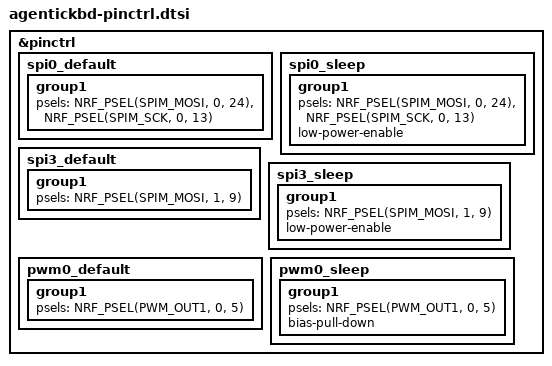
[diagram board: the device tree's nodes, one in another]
// This file was generated from a template. Edit it to match your keyboard.
// See https://docs.zephyrproject.org/4.1.0/hardware/porting/board_porting.html
// and https://docs.zephyrproject.org/4.1.0/hardware/pinctrl/index.html for
// more instructions.

#include <dt-bindings/pinctrl/nrf-pinctrl.h>

&pinctrl {
    // uart0_default: uart0_default {
    //     group1 {
    //         psels = <NRF_PSEL(UART_RX, 0, 8)>;
    //         bias-pull-up;
    //     };
    //     group2 {
    //         psels = <NRF_PSEL(UART_TX, 0, 6)>;
    //     };
    // };

    // uart0_sleep: uart0_sleep {
    //     group1 {
    //         psels = <NRF_PSEL(UART_RX, 0, 8)>,
    //                 <NRF_PSEL(UART_TX, 0, 6)>;
    //         low-power-enable;
    //     };
    // };

    spi0_default: spi0_default {
        group1 {
            psels = <NRF_PSEL(SPIM_MOSI, 0, 24)>,
                    <NRF_PSEL(SPIM_SCK, 0, 13)>;
        };
    };

    spi0_sleep: spi0_sleep {
        group1 {
            psels = <NRF_PSEL(SPIM_MOSI, 0, 24)>,
                    <NRF_PSEL(SPIM_SCK, 0, 13)>;
            low-power-enable;
        };
    };

    spi3_default: spi3_default {
        group1 {
            psels = <NRF_PSEL(SPIM_MOSI, 1, 9)>;
        };
    };

    spi3_sleep: spi3_sleep {
        group1 {
            psels = <NRF_PSEL(SPIM_MOSI, 1, 9)>;
            low-power-enable;
        };
    };

    pwm0_default: pwm0_default {
        group1 {
            psels = <NRF_PSEL(PWM_OUT1, 0, 5)>; // display bl
        };
    };

    pwm0_sleep: pwm0_sleep {
        group1 {
            psels = <NRF_PSEL(PWM_OUT1, 0, 5)>;
            bias-pull-down;
        };
    };
};
